# CY8C3866AXI_040 register map
File version: 0.1
Registers are 8-bit, read-write, no defined reset value unless marked. A register's access mark holds for its fields unless they carry their own. Offsets are from the block's base; [hi:lo] are bit positions; 'fields as' and 'values as' point back to an identical list.

## min_CNTR
Base 0x00000000
0x640A min_CNTR_COUNTER — UDB.A0 - Current Counter Value
0x642A min_CNTR_PERIOD — UDB.D0 - Assigned Period
0x643A min_CNTR_COMPARE — UDB.D1 - Assigned Compare Value
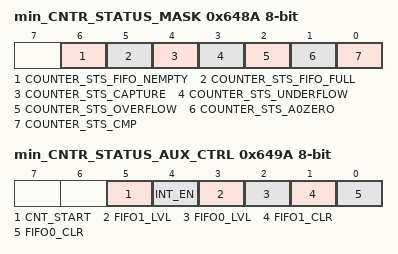
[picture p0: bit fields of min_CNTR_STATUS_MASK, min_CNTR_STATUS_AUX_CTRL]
0x648A min_CNTR_STATUS_MASK — UDB Status bits Interrupt Mask Enable Register
  [6] COUNTER_STS_FIFO_NEMPTY — FIFO Not Empty Status
  [5] COUNTER_STS_FIFO_FULL — FIFO Full Status
  [4] COUNTER_STS_CAPTURE — Capture Status
  [3] COUNTER_STS_UNDERFLOW — Underflow status
  [2] COUNTER_STS_OVERFLOW — Overflow status
  [1] COUNTER_STS_A0ZERO — A0 Zero ouput status
  [0] COUNTER_STS_CMP — Compare output status
0x649A min_CNTR_STATUS_AUX_CTRL — UDB Auxilliary Control Register
  [5] CNT_START — FIFO0 clear
    0=E_CNT_START0 (Disable counter); 1=E_CNT_START1 (Enable counter)
  [4] INT_EN
    0=E_INT_EN0 (Interrupt disabled); 1=E_INT_EN1 (Interrupt enabled)
  [3] FIFO1_LVL — FIFO level
    0=E_FIFO_LVL_0 (FIFO LVL: input mode: FIFO not full; output mode: FIFO not empty); 1=E_FIFO_LVL_1 (FIFO LVL: input mode: FIFO at least 1/2 empty; output mode: FIFO at least 1/2 full)
  [2] FIFO0_LVL — FIFO level
    values as FIFO1_LVL
  [1] FIFO1_CLR — FIFO1 clear
    0=E_FIFO_CLR_0 (Normal FIFO operation); 1=E_FIFO_CLR_1 (Clear FIFO state)
  [0] FIFO0_CLR — FIFO0 clear
    values as FIFO1_CLR

## hr_CNTR
Base 0x00000000
0x640D hr_CNTR_COUNTER — UDB.A0 - Current Counter Value
0x642D hr_CNTR_PERIOD — UDB.D0 - Assigned Period
0x643D hr_CNTR_COMPARE — UDB.D1 - Assigned Compare Value
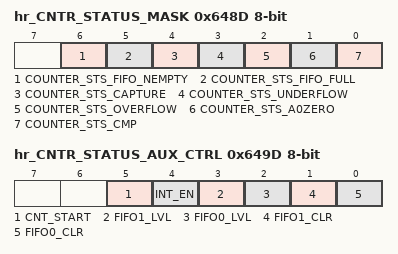
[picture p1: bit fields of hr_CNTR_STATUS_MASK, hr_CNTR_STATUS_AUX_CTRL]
0x648D hr_CNTR_STATUS_MASK — UDB Status bits Interrupt Mask Enable Register
  [6] COUNTER_STS_FIFO_NEMPTY — FIFO Not Empty Status
  [5] COUNTER_STS_FIFO_FULL — FIFO Full Status
  [4] COUNTER_STS_CAPTURE — Capture Status
  [3] COUNTER_STS_UNDERFLOW — Underflow status
  [2] COUNTER_STS_OVERFLOW — Overflow status
  [1] COUNTER_STS_A0ZERO — A0 Zero ouput status
  [0] COUNTER_STS_CMP — Compare output status
0x649D hr_CNTR_STATUS_AUX_CTRL — UDB Auxilliary Control Register
  [5] CNT_START — FIFO0 clear
    0=E_CNT_START0 (Disable counter); 1=E_CNT_START1 (Enable counter)
  [4] INT_EN
    0=E_INT_EN0 (Interrupt disabled); 1=E_INT_EN1 (Interrupt enabled)
  [3] FIFO1_LVL — FIFO level
    0=E_FIFO_LVL_0 (FIFO LVL: input mode: FIFO not full; output mode: FIFO not empty); 1=E_FIFO_LVL_1 (FIFO LVL: input mode: FIFO at least 1/2 empty; output mode: FIFO at least 1/2 full)
  [2] FIFO0_LVL — FIFO level
    values as FIFO1_LVL
  [1] FIFO1_CLR — FIFO1 clear
    0=E_FIFO_CLR_0 (Normal FIFO operation); 1=E_FIFO_CLR_1 (Clear FIFO state)
  [0] FIFO0_CLR — FIFO0 clear
    values as FIFO1_CLR

## sec_CNTR
Base 0x00000000
0x640C sec_CNTR_COUNTER — UDB.A0 - Current Counter Value
0x642C sec_CNTR_PERIOD — UDB.D0 - Assigned Period
0x643C sec_CNTR_COMPARE — UDB.D1 - Assigned Compare Value
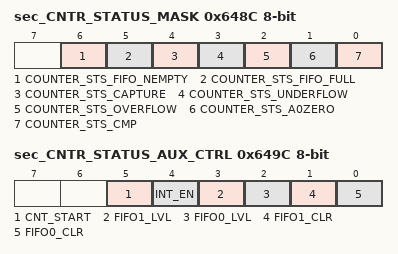
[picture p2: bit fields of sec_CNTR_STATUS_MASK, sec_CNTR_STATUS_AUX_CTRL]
0x648C sec_CNTR_STATUS_MASK — UDB Status bits Interrupt Mask Enable Register
  [6] COUNTER_STS_FIFO_NEMPTY — FIFO Not Empty Status
  [5] COUNTER_STS_FIFO_FULL — FIFO Full Status
  [4] COUNTER_STS_CAPTURE — Capture Status
  [3] COUNTER_STS_UNDERFLOW — Underflow status
  [2] COUNTER_STS_OVERFLOW — Overflow status
  [1] COUNTER_STS_A0ZERO — A0 Zero ouput status
  [0] COUNTER_STS_CMP — Compare output status
0x649C sec_CNTR_STATUS_AUX_CTRL — UDB Auxilliary Control Register
  [5] CNT_START — FIFO0 clear
    0=E_CNT_START0 (Disable counter); 1=E_CNT_START1 (Enable counter)
  [4] INT_EN
    0=E_INT_EN0 (Interrupt disabled); 1=E_INT_EN1 (Interrupt enabled)
  [3] FIFO1_LVL — FIFO level
    0=E_FIFO_LVL_0 (FIFO LVL: input mode: FIFO not full; output mode: FIFO not empty); 1=E_FIFO_LVL_1 (FIFO LVL: input mode: FIFO at least 1/2 empty; output mode: FIFO at least 1/2 full)
  [2] FIFO0_LVL — FIFO level
    values as FIFO1_LVL
  [1] FIFO1_CLR — FIFO1 clear
    0=E_FIFO_CLR_0 (Normal FIFO operation); 1=E_FIFO_CLR_1 (Clear FIFO state)
  [0] FIFO0_CLR — FIFO0 clear
    values as FIFO1_CLR
